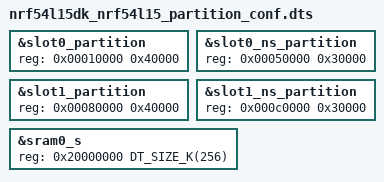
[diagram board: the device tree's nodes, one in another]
/*
 * Copyright (c) 2023 Nordic Semiconductor ASA
 *
 * SPDX-License-Identifier: Apache-2.0
 */

/*
 * Default Flash planning.
 *
 * Zephyr build with ARM TrustZone-M support, implies building Secure
 * and Non-Secure Zephyr images.
 *
 * Secure image will be placed, by default, in rram0
 * (or in slot0, if MCUboot is present).
 * Secure image will use sram0 for system memory.
 *
 * Non-Secure image will be placed in slot0_ns, and use
 * sram0_ns for system memory.
 *
 * Note that the Secure image only requires knowledge of
 * the beginning of the Non-Secure image (not its size).
 */

/*
 * TODO: NCSDK-24862: This is the same layout as 91. Update the
 * addresses for 54l.
 */

&slot0_partition {
	reg = <0x00010000 0x40000>;
};

&slot0_ns_partition {
	reg = <0x00050000 0x30000>;
};

&slot1_partition {
	reg = <0x00080000 0x40000>;
};

&slot1_ns_partition {
	reg = <0x000c0000 0x30000>;
};

/* Default SRAM planning when building with
 * ARM TrustZone-M support
 * - Lowest 128 kB SRAM allocated to Secure image (sram0_s).
 * - Upper 128 kB allocated to Non-Secure image (sram0_ns).
 */

&sram0_s {
	reg = <0x20000000 DT_SIZE_K(256)>;
};
